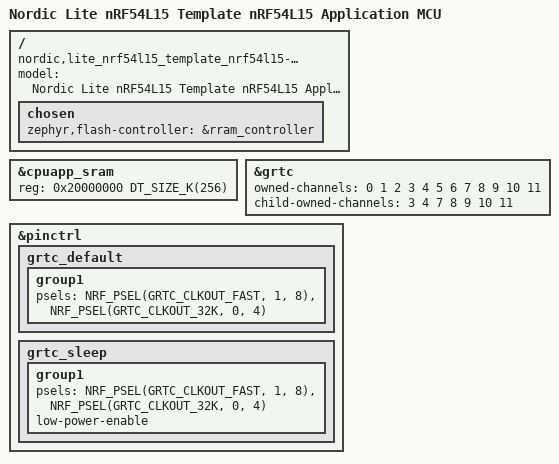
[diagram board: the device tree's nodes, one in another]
/*
 * Copyright (c) 2025 Nordic Semiconductor ASA
 *
 * SPDX-License-Identifier: Apache-2.0
 */

/ {
	compatible = "nordic,lite_nrf54l15_template_nrf54l15-cpuapp";  /* Update */
	model = "Nordic Lite nRF54L15 Template nRF54L15 Application MCU";  /* Update */

	chosen {
		zephyr,flash-controller = &rram_controller;
	};
};

/* Adjust the cpuapp_sram node to use all of SRAM for application CPU. */
&cpuapp_sram {
	reg = <0x20000000 DT_SIZE_K(256)>;
	ranges = <0x0 0x20000000 DT_SIZE_K(256)>;
};

&grtc {
	owned-channels = <0 1 2 3 4 5 6 7 8 9 10 11>;
	/* Channels 7-11 reserved for Zero Latency IRQs, 3-4 for FLPR */
	child-owned-channels = <3 4 7 8 9 10 11>;
	status = "okay";
};

&pinctrl {
	/omit-if-no-ref/ grtc_default: grtc_default {
		group1 {
			psels = <NRF_PSEL(GRTC_CLKOUT_FAST, 1, 8)>,
				<NRF_PSEL(GRTC_CLKOUT_32K, 0, 4)>;
		};
	};

	/omit-if-no-ref/ grtc_sleep: grtc_sleep {
		group1 {
			psels = <NRF_PSEL(GRTC_CLKOUT_FAST, 1, 8)>,
				<NRF_PSEL(GRTC_CLKOUT_32K, 0, 4)>;
			low-power-enable;
		};
	};
};
